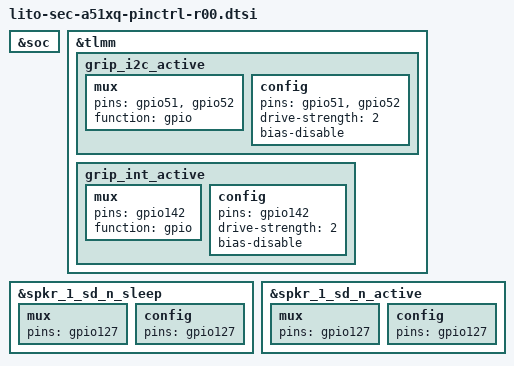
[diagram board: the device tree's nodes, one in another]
/* Copyright (c) 2019, The Linux Foundation. All rights reserved.
 *
 * This program is free software; you can redistribute it and/or modify
 * it under the terms of the GNU General Public License version 2 and
 * only version 2 as published by the Free Software Foundation.
 *
 * This program is distributed in the hope that it will be useful,
 * but WITHOUT ANY WARRANTY; without even the implied warranty of
 * MERCHANTABILITY or FITNESS FOR A PARTICULAR PURPOSE.  See the
 * GNU General Public License for more details.
 */

&soc {

};
&tlmm {
	grip_i2c_active: grip_i2c_active {
		mux {
			pins = "gpio51", "gpio52";
			function = "gpio";
		};
		config {
			pins = "gpio51", "gpio52";
			drive-strength = <2>;
			bias-disable;
		};
	};


	grip_int_active: grip_int_active {
		mux {
			pins = "gpio142";
			function = "gpio";
		};
		config {
			pins = "gpio142";
			drive-strength = <2>;
			bias-disable;
		};
	};
};

&spkr_1_sd_n_sleep {
	mux {
		pins = "gpio127";
	};

	config {
		pins = "gpio127";
	};
};

&spkr_1_sd_n_active {
	mux {
		pins = "gpio127";
	};

	config {
		pins = "gpio127";
	};
};

